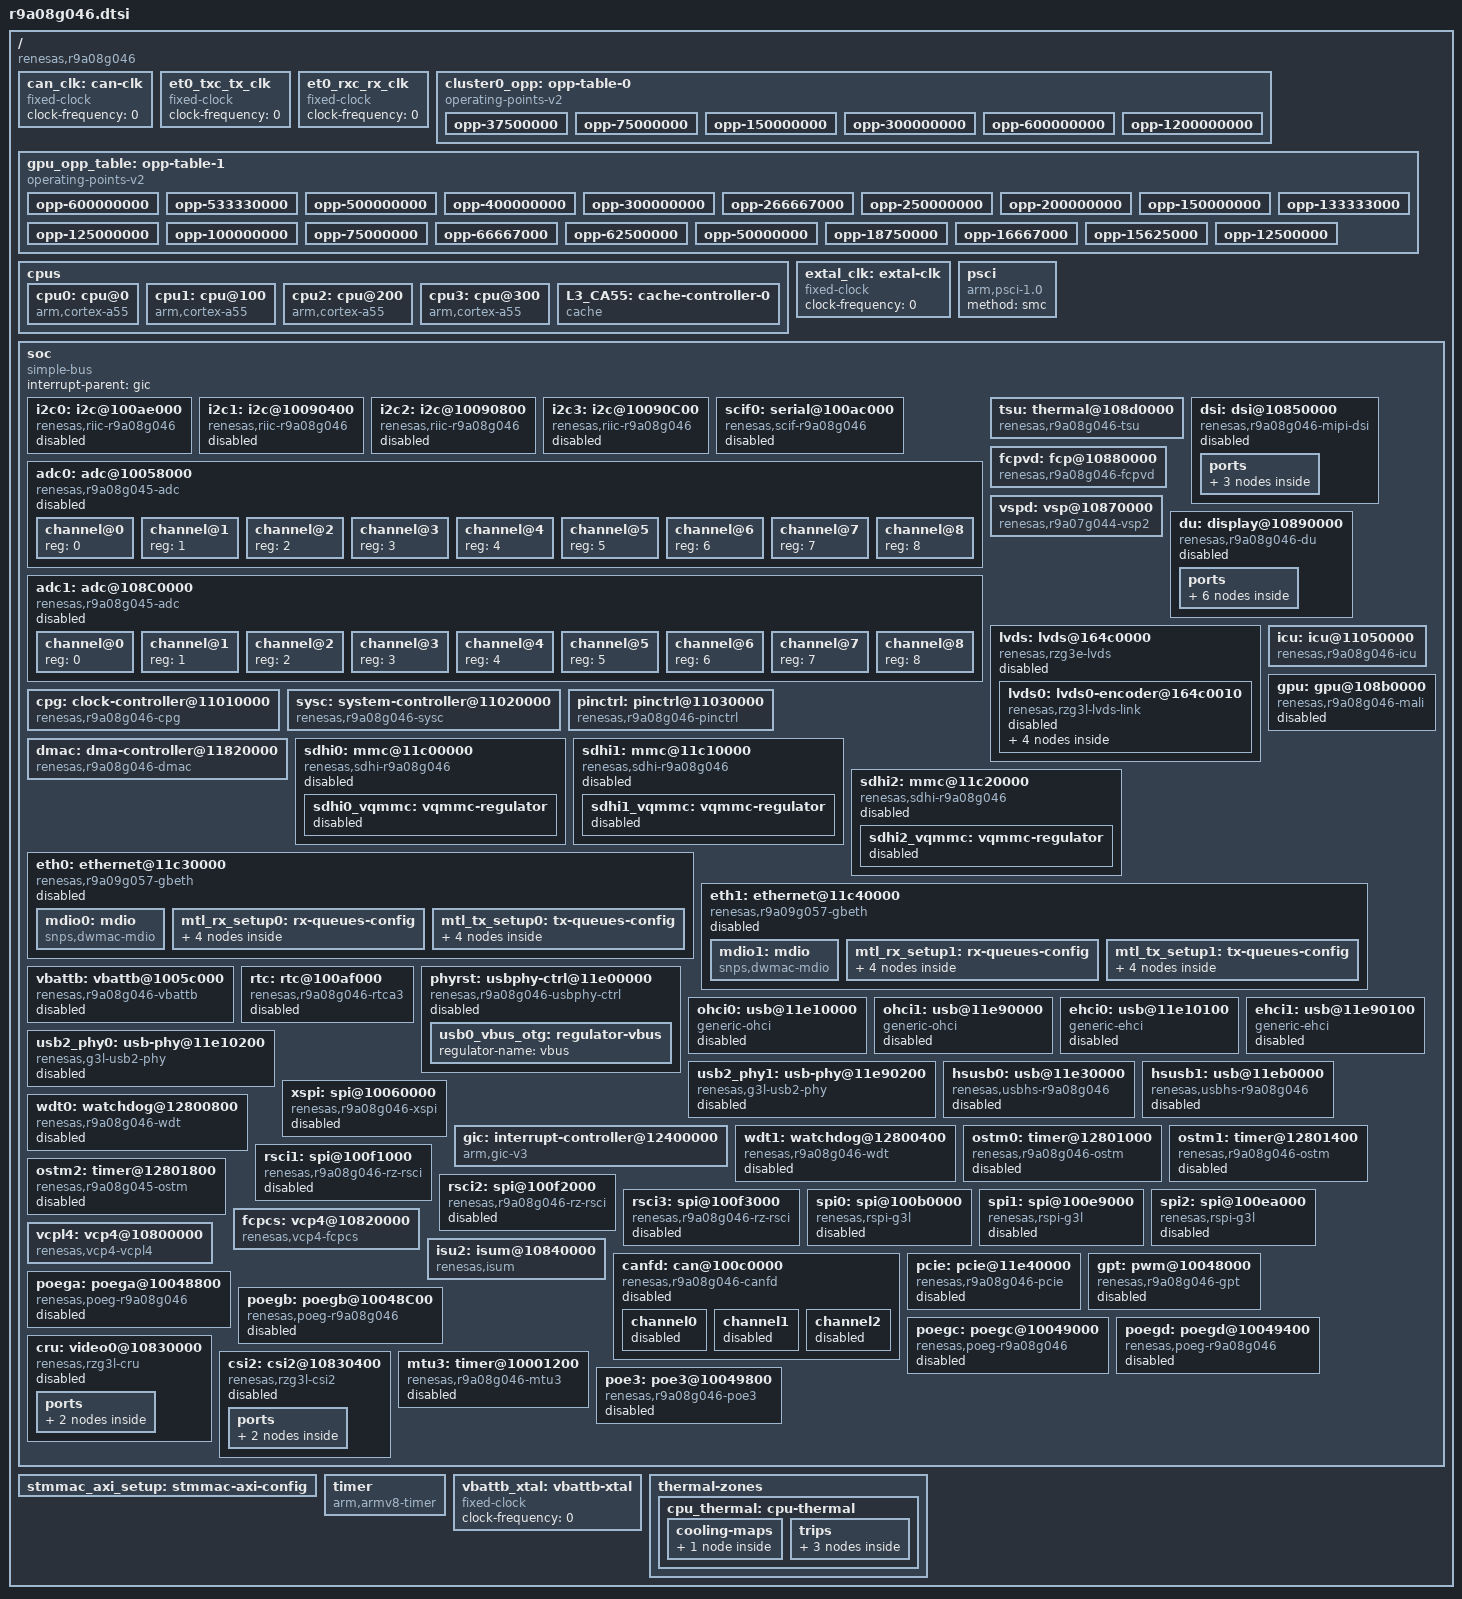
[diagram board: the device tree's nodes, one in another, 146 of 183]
// SPDX-License-Identifier: (GPL-2.0-only OR BSD-2-Clause)
/*
 * Device Tree Source for the RZ/G3L SoC
 *
 * Copyright (C) 2024 Renesas Electronics Corp.
 */

#include <dt-bindings/interrupt-controller/arm-gic.h>
#include <dt-bindings/clock/r9a08g046-cpg.h>
#include <dt-bindings/clock/renesas,r9a08g046-vbattb.h>

/ {
	compatible = "renesas,r9a08g046";
	#address-cells = <2>;
	#size-cells = <2>;

	/* External CAN clock - to be overridden by boards that provide it */
	can_clk: can-clk {
		compatible = "fixed-clock";
		#clock-cells = <0>;
		clock-frequency = <0>;
	};

	/* et0_txc_tx_clk clock input */
	et0_txc_tx_clk: et0_txc_tx_clk {
		compatible = "fixed-clock";
		#clock-cells = <0>;
		/* This value must be overridden by the board */
		clock-frequency = <0>;
	};

	/* et0_rxc_rx_clk clock input */
	et0_rxc_rx_clk: et0_rxc_rx_clk {
		compatible = "fixed-clock";
		#clock-cells = <0>;
		/* This value must be overridden by the board */
		clock-frequency = <0>;
	};

	cluster0_opp: opp-table-0 {
		compatible = "operating-points-v2";

		opp-37500000 {
			opp-hz = /bits/ 64 <37500000>;
			opp-microvolt = <1000000>;
			clock-latency-ns = <300000>;
		};
		opp-75000000 {
			opp-hz = /bits/ 64 <75000000>;
			opp-microvolt = <1000000>;
			clock-latency-ns = <300000>;
		};
		opp-150000000 {
			opp-hz = /bits/ 64 <150000000>;
			opp-microvolt = <1000000>;
			clock-latency-ns = <300000>;
		};
		opp-300000000 {
			opp-hz = /bits/ 64 <300000000>;
			opp-microvolt = <1000000>;
			clock-latency-ns = <300000>;
		};
		opp-600000000 {
			opp-hz = /bits/ 64 <600000000>;
			opp-microvolt = <1000000>;
			clock-latency-ns = <300000>;
		};
		opp-1200000000 {
			opp-hz = /bits/ 64 <1200000000>;
			opp-microvolt = <1000000>;
			clock-latency-ns = <300000>;
			opp-suspend;
		};
	};

	gpu_opp_table: opp-table-1 {
		compatible = "operating-points-v2";

		opp-600000000 {
		        opp-hz = /bits/ 64 <600000000>;
		        opp-microvolt = <1000000>;
		};

		opp-533330000 {
		        opp-hz = /bits/ 64 <533330000>;
		        opp-microvolt = <1000000>;
		};

		opp-500000000 {
		        opp-hz = /bits/ 64 <500000000>;
		        opp-microvolt = <1000000>;
		};

		opp-400000000 {
		        opp-hz = /bits/ 64 <400000000>;
		        opp-microvolt = <1000000>;
		};

		opp-300000000 {
		        opp-hz = /bits/ 64 <300000000>;
		        opp-microvolt = <1000000>;
		};

		opp-266667000 {
			opp-hz = /bits/ 64 <266667000>;
			opp-microvolt = <1000000>;
		};

		opp-250000000 {
			opp-hz = /bits/ 64 <250000000>;
			opp-microvolt = <1000000>;
		};

		opp-200000000 {
			opp-hz = /bits/ 64 <200000000>;
			opp-microvolt = <1000000>;
		};

		opp-150000000 {
			opp-hz = /bits/ 64 <150000000>;
			opp-microvolt = <1000000>;
		};

		opp-133333000 {
			opp-hz = /bits/ 64 <133333000>;
			opp-microvolt = <1000000>;
		};

		opp-125000000 {
			opp-hz = /bits/ 64 <125000000>;
			opp-microvolt = <1000000>;
		};

		opp-100000000 {
			opp-hz = /bits/ 64 <100000000>;
			opp-microvolt = <1000000>;
		};

		opp-75000000 {
			opp-hz = /bits/ 64 <75000000>;
			opp-microvolt = <1000000>;
		};

		opp-66667000 {
			opp-hz = /bits/ 64 <66667000>;
			opp-microvolt = <1000000>;
		};

		opp-62500000 {
			opp-hz = /bits/ 64 <62500000>;
			opp-microvolt = <1000000>;
		};

		opp-50000000 {
			opp-hz = /bits/ 64 <50000000>;
			opp-microvolt = <1000000>;
		};

		opp-18750000 {
			opp-hz = /bits/ 64 <18750000>;
			opp-microvolt = <1000000>;
		};

		opp-16667000 {
			opp-hz = /bits/ 64 <16667000>;
			opp-microvolt = <1000000>;
		};

		opp-15625000 {
			opp-hz = /bits/ 64 <15625000>;
			opp-microvolt = <1000000>;
		};

		opp-12500000 {
			opp-hz = /bits/ 64 <12500000>;
			opp-microvolt = <1000000>;
		};
	};

	cpus {
		#address-cells = <1>;
		#size-cells = <0>;

		cpu0: cpu@0 {
			compatible = "arm,cortex-a55";
			reg = <0>;
			device_type = "cpu";
			next-level-cache = <&L3_CA55>;
			enable-method = "psci";
			clocks = <&cpg CPG_CORE R9A08G046_CLK_IC0>;
			#cooling-cells = <2>;
			operating-points-v2 = <&cluster0_opp>;
		};

		cpu1: cpu@100 {
			compatible = "arm,cortex-a55";
			reg = <0x100>;
			device_type = "cpu";
			next-level-cache = <&L3_CA55>;
			enable-method = "psci";
			clocks = <&cpg CPG_CORE R9A08G046_CLK_IC1>;
			#cooling-cells = <2>;
			operating-points-v2 = <&cluster0_opp>;
		};

		cpu2: cpu@200 {
			compatible = "arm,cortex-a55";
			reg = <0x200>;
			device_type = "cpu";
			next-level-cache = <&L3_CA55>;
			enable-method = "psci";
			clocks = <&cpg CPG_CORE R9A08G046_CLK_IC2>;
			#cooling-cells = <2>;
			operating-points-v2 = <&cluster0_opp>;
		};

		cpu3: cpu@300 {
			compatible = "arm,cortex-a55";
			reg = <0x300>;
			device_type = "cpu";
			next-level-cache = <&L3_CA55>;
			enable-method = "psci";
			clocks = <&cpg CPG_CORE R9A08G046_CLK_IC3>;
			#cooling-cells = <2>;
			operating-points-v2 = <&cluster0_opp>;
		};

		L3_CA55: cache-controller-0 {
			compatible = "cache";
			cache-level = <3>;
			cache-unified;
			cache-size = <0x80000>;
		};
	};

	extal_clk: extal-clk {
		compatible = "fixed-clock";
		#clock-cells = <0>;
		/* This value must be overridden by the board. */
		clock-frequency = <0>;
	};

	psci {
		compatible = "arm,psci-1.0", "arm,psci-0.2";
		method = "smc";
	};

	soc: soc {
		compatible = "simple-bus";
		interrupt-parent = <&gic>;
		#address-cells = <2>;
		#size-cells = <2>;
		ranges;

		i2c0: i2c@100ae000 {
			#address-cells = <1>;
			#size-cells = <0>;
			compatible = "renesas,riic-r9a08g046";
			reg = <0 0x100AE000 0 0x400>;
			interrupts = <GIC_SPI 322 IRQ_TYPE_LEVEL_HIGH>,
				     <GIC_SPI 328 IRQ_TYPE_EDGE_RISING>,
				     <GIC_SPI 329 IRQ_TYPE_EDGE_RISING>,
				     <GIC_SPI 324 IRQ_TYPE_LEVEL_HIGH>,
				     <GIC_SPI 325 IRQ_TYPE_LEVEL_HIGH>,
				     <GIC_SPI 323 IRQ_TYPE_LEVEL_HIGH>,
				     <GIC_SPI 326 IRQ_TYPE_LEVEL_HIGH>,
				     <GIC_SPI 327 IRQ_TYPE_LEVEL_HIGH>;
			interrupt-names = "tei", "ri", "ti", "spi", "sti",
					  "naki", "ali", "tmoi";
			clocks = <&cpg CPG_MOD R9A08G046_I2C0_PCLK>;
			clock-frequency = <100000>;
			resets = <&cpg R9A08G046_I2C0_MRST>;
			power-domains = <&cpg>;
			status = "disabled";
		};

		i2c1: i2c@10090400 {
			#address-cells = <1>;
			#size-cells = <0>;
			compatible = "renesas,riic-r9a08g046";
			reg = <0 0x10090400 0 0x400>;
			interrupts = <GIC_SPI 330 IRQ_TYPE_LEVEL_HIGH>,
				     <GIC_SPI 336 IRQ_TYPE_EDGE_RISING>,
				     <GIC_SPI 337 IRQ_TYPE_EDGE_RISING>,
				     <GIC_SPI 332 IRQ_TYPE_LEVEL_HIGH>,
				     <GIC_SPI 333 IRQ_TYPE_LEVEL_HIGH>,
				     <GIC_SPI 331 IRQ_TYPE_LEVEL_HIGH>,
				     <GIC_SPI 334 IRQ_TYPE_LEVEL_HIGH>,
				     <GIC_SPI 335 IRQ_TYPE_LEVEL_HIGH>;
			interrupt-names = "tei", "ri", "ti", "spi", "sti",
					  "naki", "ali", "tmoi";
			clocks = <&cpg CPG_MOD R9A08G046_I2C1_PCLK>;
			clock-frequency = <100000>;
			resets = <&cpg R9A08G046_I2C1_MRST>;
			power-domains = <&cpg>;
			status = "disabled";
		};

		i2c2: i2c@10090800 {
			#address-cells = <1>;
			#size-cells = <0>;
			compatible = "renesas,riic-r9a08g046";
			reg = <0 0x10090800 0 0x400>;
			interrupts = <GIC_SPI 338 IRQ_TYPE_LEVEL_HIGH>,
				     <GIC_SPI 344 IRQ_TYPE_EDGE_RISING>,
				     <GIC_SPI 345 IRQ_TYPE_EDGE_RISING>,
				     <GIC_SPI 340 IRQ_TYPE_LEVEL_HIGH>,
				     <GIC_SPI 341 IRQ_TYPE_LEVEL_HIGH>,
				     <GIC_SPI 339 IRQ_TYPE_LEVEL_HIGH>,
				     <GIC_SPI 342 IRQ_TYPE_LEVEL_HIGH>,
				     <GIC_SPI 343 IRQ_TYPE_LEVEL_HIGH>;
			interrupt-names = "tei", "ri", "ti", "spi", "sti",
					  "naki", "ali", "tmoi";
			clocks = <&cpg CPG_MOD R9A08G046_I2C2_PCLK>;
			clock-frequency = <100000>;
			resets = <&cpg R9A08G046_I2C2_MRST>;
			power-domains = <&cpg>;
			status = "disabled";
		};

		i2c3: i2c@10090C00 {
			#address-cells = <1>;
			#size-cells = <0>;
			compatible = "renesas,riic-r9a08g046";
			reg = <0 0x10090C00 0 0x400>;
			interrupts = <GIC_SPI 346 IRQ_TYPE_LEVEL_HIGH>,
				     <GIC_SPI 352 IRQ_TYPE_EDGE_RISING>,
				     <GIC_SPI 353 IRQ_TYPE_EDGE_RISING>,
				     <GIC_SPI 348 IRQ_TYPE_LEVEL_HIGH>,
				     <GIC_SPI 349 IRQ_TYPE_LEVEL_HIGH>,
				     <GIC_SPI 347 IRQ_TYPE_LEVEL_HIGH>,
				     <GIC_SPI 350 IRQ_TYPE_LEVEL_HIGH>,
				     <GIC_SPI 351 IRQ_TYPE_LEVEL_HIGH>;
			interrupt-names = "tei", "ri", "ti", "spi", "sti",
					  "naki", "ali", "tmoi";
			clocks = <&cpg CPG_MOD R9A08G046_I2C3_PCLK>;
			clock-frequency = <100000>;
			resets = <&cpg R9A08G046_I2C3_MRST>;
			power-domains = <&cpg>;
			status = "disabled";
		};

		scif0: serial@100ac000 {
			compatible = "renesas,scif-r9a08g046", "renesas,scif-r9a07g044";
			reg = <0 0x100ac000 0 0x400>;
			interrupts = <GIC_SPI 386 IRQ_TYPE_LEVEL_HIGH>,
				     <GIC_SPI 388 IRQ_TYPE_LEVEL_HIGH>,
				     <GIC_SPI 389 IRQ_TYPE_LEVEL_HIGH>,
				     <GIC_SPI 387 IRQ_TYPE_LEVEL_HIGH>,
				     <GIC_SPI 390 IRQ_TYPE_LEVEL_HIGH>,
				     <GIC_SPI 390 IRQ_TYPE_LEVEL_HIGH>;
			interrupt-names = "eri", "rxi", "txi",
					  "bri", "dri", "tei";
			clocks = <&cpg CPG_MOD R9A08G046_SCIF0_CLK_PCK>;
			clock-names = "fck";
			power-domains = <&cpg>;
			resets = <&cpg R9A08G046_SCIF0_RST_SYSTEM_N>;
			status = "disabled";
		};

		adc0: adc@10058000 {
			compatible = "renesas,r9a08g045-adc";
			reg = <0 0x10058000 0 0x400>;
			interrupts = <GIC_SPI 377 IRQ_TYPE_EDGE_RISING>;
			clocks = <&cpg CPG_MOD R9A08G046_ADC0_ADCLK>,
				 <&cpg CPG_MOD R9A08G046_ADC0_PCLK>;
			clock-names = "adclk", "pclk";
			resets = <&cpg R9A08G046_ADC0_PRESETN>,
				 <&cpg R9A08G046_ADC0_ADRST_N>;
			reset-names = "presetn", "adrst-n";
			power-domains = <&cpg>;
			status = "disabled";

			#io-channel-cells = <1>;
			#address-cells = <1>;
			#size-cells = <0>;

			channel@0 {
				reg = <0>;
			};

			channel@1 {
				reg = <1>;
			};

			channel@2 {
				reg = <2>;
			};

			channel@3 {
				reg = <3>;
			};

			channel@4 {
				reg = <4>;
			};

			channel@5 {
				reg = <5>;
			};

			channel@6 {
				reg = <6>;
			};

			channel@7 {
				reg = <7>;
			};

			channel@8 {
				reg = <8>;
			};
		};

		adc1: adc@108C0000 {
			compatible = "renesas,r9a08g045-adc";
			reg = <0 0x108C0000 0 0x400>;
			interrupts = <GIC_SPI 378 IRQ_TYPE_EDGE_RISING>;
			clocks = <&cpg CPG_MOD R9A08G046_ADC1_ADCLK>,
				 <&cpg CPG_MOD R9A08G046_ADC1_PCLK>;
			clock-names = "adclk", "pclk";
			resets = <&cpg R9A08G046_ADC1_PRESETN>,
				 <&cpg R9A08G046_ADC1_ADRST_N>;
			reset-names = "presetn", "adrst-n";
			power-domains = <&cpg>;
			status = "disabled";

			#io-channel-cells = <1>;
			#address-cells = <1>;
			#size-cells = <0>;

			channel@0 {
				reg = <0>;
			};

			channel@1 {
				reg = <1>;
			};

			channel@2 {
				reg = <2>;
			};

			channel@3 {
				reg = <3>;
			};

			channel@4 {
				reg = <4>;
			};

			channel@5 {
				reg = <5>;
			};

			channel@6 {
				reg = <6>;
			};

			channel@7 {
				reg = <7>;
			};

			channel@8 {
				reg = <8>;
			};
		};

		tsu: thermal@108d0000 {
			compatible = "renesas,r9a08g046-tsu";
			reg = <0 0x108d0000 0 0x1000>;
			clocks = <&cpg CPG_MOD R9A08G046_TSU_PCLK>;
			resets = <&cpg R9A08G046_TSU_PRESETN>;
			power-domains = <&cpg>;
			#thermal-sensor-cells = <0>;
			io-channels = <&adc1 8>;
			io-channel-names = "tsu";
		};

		dsi: dsi@10850000 {
			compatible = "renesas,r9a08g046-mipi-dsi",
				     "renesas,rzg2l-mipi-dsi";
			reg = <0 0x10850000 0 0x20000>;
			interrupts = <GIC_SPI 170 IRQ_TYPE_LEVEL_HIGH>,
				     <GIC_SPI 171 IRQ_TYPE_LEVEL_HIGH>,
				     <GIC_SPI 172 IRQ_TYPE_LEVEL_HIGH>,
				     <GIC_SPI 173 IRQ_TYPE_LEVEL_HIGH>,
				     <GIC_SPI 174 IRQ_TYPE_LEVEL_HIGH>,
				     <GIC_SPI 175 IRQ_TYPE_LEVEL_HIGH>,
				     <GIC_SPI 176 IRQ_TYPE_LEVEL_HIGH>;
			interrupt-names = "seq0", "seq1", "vin1", "rcv",
					  "ferr", "ppi", "debug";
			clocks = <&cpg CPG_MOD R9A08G046_MIPI_DSI_SYSCLK>,
				 <&cpg CPG_MOD R9A08G046_MIPI_DSI_ACLK>,
				 <&cpg CPG_MOD R9A08G046_MIPI_DSI_PCLK>,
				 <&cpg CPG_MOD R9A08G046_MIPI_DSI_VCLK>,
				 <&cpg CPG_MOD R9A08G046_MIPI_DSI_LPCLK>;
			clock-names = "sysclk", "aclk", "pclk", "vclk", "lpclk";
			resets = <&cpg R9A08G046_MIPI_DSI_CMN_RSTB>,
				 <&cpg R9A08G046_MIPI_DSI_ARESET_N>,
				 <&cpg R9A08G046_MIPI_DSI_PRESET_N>;
			reset-names = "rst", "arst", "prst";
			power-domains = <&cpg>;
			status = "disabled";

			ports {
				#address-cells = <1>;
				#size-cells = <0>;

				port@0 {
					reg = <0>;
					dsi0_in: endpoint {
						remote-endpoint = <&du_out_dsi0>;
					};
				};

				port@1 {
					reg = <1>;
				};
			};
		};

		fcpvd: fcp@10880000 {
			compatible = "renesas,r9a08g046-fcpvd",
				     "renesas,fcpv";
			reg = <0 0x10880000 0 0x10000>;
			clocks = <&cpg CPG_MOD R9A08G046_LCDC_CLK_A>,
				 <&cpg CPG_MOD R9A08G046_LCDC_CLK_P>,
				 <&cpg CPG_MOD R9A08G046_LCDC_CLK_D>;
			clock-names = "aclk", "pclk", "vclk";
			resets = <&cpg R9A08G046_LCDC_RESET_N>;
			power-domains = <&cpg>;
		};

		vspd: vsp@10870000 {
			compatible = "renesas,r9a07g044-vsp2";
			reg = <0 0x10870000 0 0x10000>;
			interrupts = <GIC_SPI 177 IRQ_TYPE_LEVEL_HIGH>;
			clocks = <&cpg CPG_MOD R9A08G046_LCDC_CLK_A>,
				 <&cpg CPG_MOD R9A08G046_LCDC_CLK_P>,
				 <&cpg CPG_MOD R9A08G046_LCDC_CLK_D>;
			clock-names = "aclk", "pclk", "vclk";
			resets = <&cpg R9A08G046_LCDC_RESET_N>;
			power-domains = <&cpg>;
			renesas,fcp = <&fcpvd>;
		};

		du: display@10890000 {
			compatible = "renesas,r9a08g046-du";
			reg = <0 0x10890000 0 0x10000>;
			interrupts = <GIC_SPI 178 IRQ_TYPE_LEVEL_HIGH>;
			clocks = <&cpg CPG_MOD R9A08G046_LCDC_CLK_A>,
				 <&cpg CPG_MOD R9A08G046_LCDC_CLK_P>,
				 <&cpg CPG_MOD R9A08G046_LCDC_CLK_D>;
			clock-names = "aclk", "pclk", "vclk";
			power-domains = <&cpg>;
			resets = <&cpg R9A08G046_LCDC_RESET_N>,
				 <&cpg R9A08G046_LCDC_RESET_N>;
			renesas,vsps = <&vspd 0>;
			status = "disabled";

			ports {
				#address-cells = <1>;
				#size-cells = <0>;

				port@0 {
					reg = <0>;
					du_out_dsi0: endpoint {
						remote-endpoint = <&dsi0_in>;
					};
				};

				port@1 {
					reg = <1>;
					du_out_rgb: endpoint {
					};
				};

				port@2 {
					reg = <2>;
					du_out_lvds0: endpoint {
						remote-endpoint = <&lvds0_in>;
					};
				};
			};
		};


		lvds: lvds@164c0000 {
			compatible = "renesas,rzg3e-lvds";
			reg = <0x0 0x108a0000 0x0 0x10>;
			clocks = <&cpg CPG_MOD R9A08G046_MIPI_DSI_PCLK>;
			clock-names = "dsi_pclk";
			resets = <&cpg R9A08G046_LVDS_RESET_N>,
				 <&cpg R9A08G046_MIPI_DSI_PRESET_N>;
			power-domains = <&cpg>;
			status = "disabled";
			ranges;
			#address-cells = <2>;
			#size-cells = <2>;

			lvds0: lvds0-encoder@164c0010 {
				compatible = "renesas,rzg3l-lvds-link";
				reg = <0x0 0x108a0010 0x0 0x8>;
				clocks = <&cpg CPG_MOD R9A08G046_LVDS_PLLCLK>,
					 <&cpg CPG_MOD R9A08G046_LVDS_CLK_DOT0>;
				clock-names = "phyclk", "dotclk";
				power-domains = <&cpg>;
				renesas,id = <0>;
				status = "disabled";

				ports {
					#address-cells = <1>;
					#size-cells = <0>;

					port@0 {
						reg = <0>;
						lvds0_in: endpoint {
							remote-endpoint = <&du_out_lvds0>;
						};
					};

					port@1 {
						reg = <1>;
					};
				};
			};
		};

		cpg: clock-controller@11010000 {
			compatible = "renesas,r9a08g046-cpg";
			reg = <0 0x11010000 0 0x10000>;
			clocks = <&extal_clk>,
				 <&et0_txc_tx_clk>, <&et0_rxc_rx_clk>;
			clock-names = "extal",
				"et0_txc_tx_clk_in", "et0_rxc_rx_clk_in";
			#clock-cells = <2>;
			#reset-cells = <1>;
			#power-domain-cells = <0>;
		};

		sysc: system-controller@11020000 {
			compatible = "renesas,r9a08g046-sysc", "syscon";
			reg = <0 0x11020000 0 0x10000>;
			interrupts = <GIC_SPI 44 IRQ_TYPE_LEVEL_HIGH>,
				     <GIC_SPI 45 IRQ_TYPE_LEVEL_HIGH>,
				     <GIC_SPI 46 IRQ_TYPE_LEVEL_HIGH>,
				     <GIC_SPI 47 IRQ_TYPE_LEVEL_HIGH>;
			interrupt-names = "lpm_int", "ca55stbydone_int",
					  "cm33stbyr_int", "ca55_deny";
		};

		pinctrl: pinctrl@11030000 {
			compatible = "renesas,r9a08g046-pinctrl";
			syscon = <&sysc>;
			reg = <0 0x11030000 0 0x10000>;
			gpio-controller;
			#gpio-cells = <2>;
			interrupt-controller;
			#interrupt-cells = <2>;
			gpio-ranges = <&pinctrl 0 0 232>;
			interrupt-parent = <&icu>;
			clocks = <&cpg CPG_MOD R9A08G046_GPIO_HCLK>;
			power-domains = <&cpg>;
			resets = <&cpg R9A08G046_GPIO_RSTN>,
				 <&cpg R9A08G046_GPIO_PORT_RESETN>,
				 <&cpg R9A08G046_GPIO_SPARE_RESETN>;
		};

		icu: icu@11050000 {
			compatible = "renesas,r9a08g046-icu";
			#interrupt-cells = <2>;
			#address-cells = <0>;
			interrupt-controller;
			reg = <0 0x11050000 0 0x10000>;
			interrupts = <GIC_SPI 0 IRQ_TYPE_LEVEL_HIGH>,
				     <GIC_SPI 1 IRQ_TYPE_LEVEL_HIGH>,
				     <GIC_SPI 2 IRQ_TYPE_LEVEL_HIGH>,
				     <GIC_SPI 3 IRQ_TYPE_LEVEL_HIGH>,
				     <GIC_SPI 4 IRQ_TYPE_LEVEL_HIGH>,
				     <GIC_SPI 5 IRQ_TYPE_LEVEL_HIGH>,
				     <GIC_SPI 6 IRQ_TYPE_LEVEL_HIGH>,
				     <GIC_SPI 7 IRQ_TYPE_LEVEL_HIGH>,
				     <GIC_SPI 8 IRQ_TYPE_LEVEL_HIGH>,
				     <GIC_SPI 529 IRQ_TYPE_LEVEL_HIGH>,
				     <GIC_SPI 530 IRQ_TYPE_LEVEL_HIGH>,
				     <GIC_SPI 531 IRQ_TYPE_LEVEL_HIGH>,
				     <GIC_SPI 532 IRQ_TYPE_LEVEL_HIGH>,
				     <GIC_SPI 533 IRQ_TYPE_LEVEL_HIGH>,
				     <GIC_SPI 534 IRQ_TYPE_LEVEL_HIGH>,
				     <GIC_SPI 535 IRQ_TYPE_LEVEL_HIGH>,
				     <GIC_SPI 536 IRQ_TYPE_LEVEL_HIGH>,
				     <GIC_SPI 505 IRQ_TYPE_LEVEL_HIGH>,
				     <GIC_SPI 506 IRQ_TYPE_LEVEL_HIGH>,
				     <GIC_SPI 507 IRQ_TYPE_LEVEL_HIGH>,
				     <GIC_SPI 508 IRQ_TYPE_LEVEL_HIGH>,
				     <GIC_SPI 509 IRQ_TYPE_LEVEL_HIGH>,
				     <GIC_SPI 510 IRQ_TYPE_LEVEL_HIGH>,
				     <GIC_SPI 511 IRQ_TYPE_LEVEL_HIGH>,
				     <GIC_SPI 512 IRQ_TYPE_LEVEL_HIGH>,
				     <GIC_SPI 513 IRQ_TYPE_LEVEL_HIGH>,
				     <GIC_SPI 514 IRQ_TYPE_LEVEL_HIGH>,
				     <GIC_SPI 515 IRQ_TYPE_LEVEL_HIGH>,
				     <GIC_SPI 516 IRQ_TYPE_LEVEL_HIGH>,
				     <GIC_SPI 517 IRQ_TYPE_LEVEL_HIGH>,
				     <GIC_SPI 518 IRQ_TYPE_LEVEL_HIGH>,
				     <GIC_SPI 519 IRQ_TYPE_LEVEL_HIGH>,
				     <GIC_SPI 520 IRQ_TYPE_LEVEL_HIGH>,
				     <GIC_SPI 521 IRQ_TYPE_LEVEL_HIGH>,
				     <GIC_SPI 522 IRQ_TYPE_LEVEL_HIGH>,
				     <GIC_SPI 523 IRQ_TYPE_LEVEL_HIGH>,
				     <GIC_SPI 524 IRQ_TYPE_LEVEL_HIGH>,
				     <GIC_SPI 525 IRQ_TYPE_LEVEL_HIGH>,
				     <GIC_SPI 526 IRQ_TYPE_LEVEL_HIGH>,
				     <GIC_SPI 527 IRQ_TYPE_LEVEL_HIGH>,
				     <GIC_SPI 528 IRQ_TYPE_LEVEL_HIGH>,
				     <GIC_SPI 529 IRQ_TYPE_LEVEL_HIGH>,
				     <GIC_SPI 530 IRQ_TYPE_LEVEL_HIGH>,
				     <GIC_SPI 531 IRQ_TYPE_LEVEL_HIGH>,
				     <GIC_SPI 532 IRQ_TYPE_LEVEL_HIGH>,
				     <GIC_SPI 533 IRQ_TYPE_LEVEL_HIGH>,
				     <GIC_SPI 534 IRQ_TYPE_LEVEL_HIGH>,
				     <GIC_SPI 535 IRQ_TYPE_LEVEL_HIGH>,
				     <GIC_SPI 536 IRQ_TYPE_LEVEL_HIGH>,
				     <GIC_SPI 33 IRQ_TYPE_LEVEL_HIGH>,
				     <GIC_SPI 35 IRQ_TYPE_LEVEL_HIGH>,
				     <GIC_SPI 36 IRQ_TYPE_LEVEL_HIGH>,
				     <GIC_SPI 37 IRQ_TYPE_LEVEL_HIGH>;
			interrupt-names = "nmi",
					  "irq0", "irq1", "irq2", "irq3",
					  "irq4", "irq5", "irq6", "irq7",
					  "irq8", "irq9", "irq10", "irq11",
					  "irq12", "irq13", "irq14", "irq15",
					  "tint0", "tint1", "tint2", "tint3",
					  "tint4", "tint5", "tint6", "tint7",
					  "tint8", "tint9", "tint10", "tint11",
					  "tint12", "tint13", "tint14", "tint15",
					  "tint16", "tint17", "tint18", "tint19",
					  "tint20", "tint21", "tint22", "tint23",
					  "tint24", "tint25", "tint26", "tint27",
					  "tint28", "tint29", "tint30", "tint31",
					  "bus-err", "ec7tie1-0", "ec7tie2-0",
					  "ec7tiovf-0";
			clocks = <&cpg CPG_MOD R9A08G046_IA55_CLK>,
				 <&cpg CPG_MOD R9A08G046_IA55_PCLK>;
			clock-names = "clk", "pclk";
			power-domains = <&cpg>;
			resets = <&cpg R9A08G046_IA55_RESETN>;
		};

		dmac: dma-controller@11820000 {
			compatible = "renesas,r9a08g046-dmac",
				     "renesas,rz-dmac";
			reg = <0 0x11820000 0 0x10000>,
			      <0 0x11830000 0 0x10000>;
			interrupts = <GIC_SPI 153 IRQ_TYPE_EDGE_RISING>,
				     <GIC_SPI 154 IRQ_TYPE_EDGE_RISING>,
				     <GIC_SPI 155 IRQ_TYPE_EDGE_RISING>,
				     <GIC_SPI 156 IRQ_TYPE_EDGE_RISING>,
				     <GIC_SPI 157 IRQ_TYPE_EDGE_RISING>,
				     <GIC_SPI 158 IRQ_TYPE_EDGE_RISING>,
				     <GIC_SPI 159 IRQ_TYPE_EDGE_RISING>,
				     <GIC_SPI 160 IRQ_TYPE_EDGE_RISING>,
				     <GIC_SPI 161 IRQ_TYPE_EDGE_RISING>,
				     <GIC_SPI 162 IRQ_TYPE_EDGE_RISING>,
				     <GIC_SPI 163 IRQ_TYPE_EDGE_RISING>,
				     <GIC_SPI 164 IRQ_TYPE_EDGE_RISING>,
				     <GIC_SPI 165 IRQ_TYPE_EDGE_RISING>,
				     <GIC_SPI 166 IRQ_TYPE_EDGE_RISING>,
				     <GIC_SPI 167 IRQ_TYPE_EDGE_RISING>,
				     <GIC_SPI 168 IRQ_TYPE_EDGE_RISING>,
				     <GIC_SPI 169 IRQ_TYPE_EDGE_RISING>;
			interrupt-names = "error",
					  "ch0", "ch1", "ch2", "ch3",
					  "ch4", "ch5", "ch6", "ch7",
					  "ch8", "ch9", "ch10", "ch11",
					  "ch12", "ch13", "ch14", "ch15";
			clocks = <&cpg CPG_MOD R9A08G046_DMAC_ACLK>,
				 <&cpg CPG_MOD R9A08G046_DMAC_PCLK>;
			clock-names = "main", "register";
			power-domains = <&cpg>;
			resets = <&cpg R9A08G046_DMAC_ARESETN>,
				 <&cpg R9A08G046_DMAC_RST_ASYNC>;
			reset-names = "arst", "rst_async";
			#dma-cells = <1>;
			dma-channels = <16>;
		};

		sdhi0: mmc@11c00000  {
			compatible = "renesas,sdhi-r9a08g046", "renesas,rzg2l-sdhi";
			reg = <0x0 0x11c00000 0 0x10000>;
			interrupts = <GIC_SPI 130 IRQ_TYPE_LEVEL_HIGH>,
				     <GIC_SPI 131 IRQ_TYPE_LEVEL_HIGH>;
			clocks = <&cpg CPG_MOD R9A08G046_SDHI0_IMCLK>,
				 <&cpg CPG_MOD R9A08G046_SDHI0_CLK_HS>,
				 <&cpg CPG_MOD R9A08G046_SDHI0_IMCLK2>,
				 <&cpg CPG_MOD R9A08G046_SDHI0_IACLKS>,
				 <&cpg CPG_MOD R9A08G046_SDHI0_IACLKM>;
			clock-names = "core", "clkh", "cd", "aclk", "aclkm";
			resets = <&cpg R9A08G046_SDHI0_IXRST>,
				 <&cpg R9A08G046_SDHI0_IXRSTAXIM>,
				 <&cpg R9A08G046_SDHI0_IXRSTAXIS>;
			reset-names = "rst", "axim", "axis";
			power-domains = <&cpg>;
			status = "disabled";

			sdhi0_vqmmc: vqmmc-regulator {
				regulator-name = "SDHI0-VQMMC";
				regulator-min-microvolt = <1800000>;
				regulator-max-microvolt = <3300000>;
				status = "disabled";
			};
		};

		sdhi1: mmc@11c10000  {
			compatible = "renesas,sdhi-r9a08g046", "renesas,rzg2l-sdhi";
			reg = <0x0 0x11c10000 0 0x10000>;
			interrupts = <GIC_SPI 132 IRQ_TYPE_LEVEL_HIGH>,
				     <GIC_SPI 133 IRQ_TYPE_LEVEL_HIGH>;
			clocks = <&cpg CPG_MOD R9A08G046_SDHI1_IMCLK>,
				 <&cpg CPG_MOD R9A08G046_SDHI1_CLK_HS>,
				 <&cpg CPG_MOD R9A08G046_SDHI1_IMCLK2>,
				 <&cpg CPG_MOD R9A08G046_SDHI1_IACLKS>,
				 <&cpg CPG_MOD R9A08G046_SDHI1_IACLKM>;
			clock-names = "core", "clkh", "cd", "aclk", "iclkm";
			resets = <&cpg R9A08G046_SDHI1_IXRST>,
				 <&cpg R9A08G046_SDHI1_IXRSTAXIM>,
				 <&cpg R9A08G046_SDHI1_IXRSTAXIS>;
			reset-names = "rst", "axim", "axis";
			power-domains = <&cpg>;
			status = "disabled";

			sdhi1_vqmmc: vqmmc-regulator {
				regulator-name = "SDHI1-VQMMC";
				regulator-min-microvolt = <1800000>;
				regulator-max-microvolt = <3300000>;
				status = "disabled";
			};
		};

		sdhi2: mmc@11c20000  {
			compatible = "renesas,sdhi-r9a08g046", "renesas,rzg2l-sdhi";
			reg = <0x0 0x11c20000 0 0x10000>;
			interrupts = <GIC_SPI 134 IRQ_TYPE_LEVEL_HIGH>,
				     <GIC_SPI 135 IRQ_TYPE_LEVEL_HIGH>;
			clocks = <&cpg CPG_MOD R9A08G046_SDHI2_IMCLK>,
				 <&cpg CPG_MOD R9A08G046_SDHI2_CLK_HS>,
				 <&cpg CPG_MOD R9A08G046_SDHI2_IMCLK2>,
				 <&cpg CPG_MOD R9A08G046_SDHI2_IACLKS>,
				 <&cpg CPG_MOD R9A08G046_SDHI2_IACLKM>;
			clock-names = "core", "clkh", "cd", "aclk", "iclkm";
			resets = <&cpg R9A08G046_SDHI2_IXRST>,
				 <&cpg R9A08G046_SDHI2_IXRSTAXIM>,
				 <&cpg R9A08G046_SDHI2_IXRSTAXIS>;
			reset-names = "rst", "axim", "axis";
			power-domains = <&cpg>;
			status = "disabled";

			sdhi2_vqmmc: vqmmc-regulator {
				regulator-name = "SDHI2-VQMMC";
				regulator-min-microvolt = <1800000>;
				regulator-max-microvolt = <3300000>;
				status = "disabled";
			};
		};

		gpu: gpu@108b0000 {
			compatible = "renesas,r9a08g046-mali",
				     "arm,mali-bifrost";
			reg = <0x0 0x108b0000 0x0 0x10000>;
			interrupts = <GIC_SPI 179 IRQ_TYPE_LEVEL_HIGH>,
				     <GIC_SPI 180 IRQ_TYPE_LEVEL_HIGH>,
				     <GIC_SPI 181 IRQ_TYPE_LEVEL_HIGH>,
				     <GIC_SPI 182 IRQ_TYPE_LEVEL_HIGH>;
			interrupt-names = "gpu", "job", "mmu", "event";
			clocks = <&cpg CPG_MOD R9A08G046_GE3D_CLK>,
				 <&cpg CPG_MOD R9A08G046_GE3D_AXI_CLK>,
				 <&cpg CPG_MOD R9A08G046_GE3D_ACE_CLK>;
			clock-names = "gpu", "bus", "bus_ace";
			power-domains = <&cpg>;
			resets = <&cpg R9A08G046_GE3D_RESETN>,
				 <&cpg R9A08G046_GE3D_AXI_RESETN>,
				 <&cpg R9A08G046_GE3D_ACE_RESETN>;
			reset-names = "rst", "axi_rst", "ace_rst";
			operating-points-v2 = <&gpu_opp_table>;
			status = "disabled";
		};

		eth0: ethernet@11c30000 {
			compatible = "renesas,r9a09g057-gbeth", "renesas,rzv2h-gbeth",
				     "snps,dwmac-5.20";
			reg = <0 0x11c30000 0 0x10000>;
			interrupts = <GIC_SPI 78 IRQ_TYPE_LEVEL_HIGH>,
				     <GIC_SPI 80 IRQ_TYPE_LEVEL_HIGH>,
				     <GIC_SPI 79 IRQ_TYPE_LEVEL_HIGH>,
				     <GIC_SPI 85 IRQ_TYPE_LEVEL_HIGH>,
				     <GIC_SPI 86 IRQ_TYPE_LEVEL_HIGH>,
				     <GIC_SPI 87 IRQ_TYPE_LEVEL_HIGH>,
				     <GIC_SPI 88 IRQ_TYPE_LEVEL_HIGH>,
				     <GIC_SPI 81 IRQ_TYPE_LEVEL_HIGH>,
				     <GIC_SPI 82 IRQ_TYPE_LEVEL_HIGH>,
				     <GIC_SPI 83 IRQ_TYPE_LEVEL_HIGH>,
				     <GIC_SPI 84 IRQ_TYPE_LEVEL_HIGH>;
			interrupt-names = "macirq", "eth_wake_irq", "eth_lpi",
					  "rx-queue-0", "rx-queue-1", "rx-queue-2",
					  "rx-queue-3", "tx-queue-0", "tx-queue-1",
					  "tx-queue-2", "tx-queue-3";
			clocks =  <&cpg CPG_MOD R9A08G046_ETH0_CLK_AXI>,
				  <&cpg CPG_MOD R9A08G046_ETH0_CLK_CHI>,
				  <&cpg CPG_MOD R9A08G046_ETH0_CLK_PTP_REF_I>,
				  <&cpg CPG_MOD R9A08G046_ETH0_CLK_TX_I>,
				  <&cpg CPG_MOD R9A08G046_ETH0_CLK_RX_I>,
				  <&cpg CPG_MOD R9A08G046_ETH0_CLK_TX_180_I>,
				  <&cpg CPG_MOD R9A08G046_ETH0_CLK_RX_180_I>;
			clock-names = "stmmaceth", "pclk", "ptp_ref",
				      "tx", "rx", "tx-180", "rx-180";
			resets = <&cpg R9A08G046_ETH0_ARESET_N>;
			power-domains = <&cpg>;
			snps,multicast-filter-bins = <256>;
			snps,perfect-filter-entries = <128>;
			rx-fifo-depth = <8192>;
			tx-fifo-depth = <8192>;
			snps,fixed-burst;
			snps,no-pbl-x8;
			snps,force_thresh_dma_mode;
			snps,en-tx-lpi-clockgating;
			snps,axi-config = <&stmmac_axi_setup>;
			snps,mtl-rx-config = <&mtl_rx_setup0>;
			snps,mtl-tx-config = <&mtl_tx_setup0>;
			snps,txpbl = <32>;
			snps,rxpbl = <32>;
			status = "disabled";

			mdio0: mdio {
				compatible = "snps,dwmac-mdio";
				#address-cells = <1>;
				#size-cells = <0>;
			};

			mtl_rx_setup0: rx-queues-config {
				snps,rx-queues-to-use = <4>;
				snps,rx-sched-sp;

				queue0 {
					snps,dcb-algorithm;
					snps,priority = <0x1>;
					snps,map-to-dma-channel = <0>;
				};

				queue1 {
					snps,dcb-algorithm;
					snps,priority = <0x2>;
					snps,map-to-dma-channel = <1>;
				};

				queue2 {
					snps,dcb-algorithm;
					snps,priority = <0x4>;
					snps,map-to-dma-channel = <2>;
				};

				queue3 {
					snps,dcb-algorithm;
					snps,priority = <0x8>;
					snps,map-to-dma-channel = <3>;
				};
			};

			mtl_tx_setup0: tx-queues-config {
				snps,tx-queues-to-use = <4>;
				snps,tx-sched-wrr;

				queue0 {
					snps,weight = <0x10>;
					snps,dcb-algorithm;
					snps,priority = <0x1>;
				};

				queue1 {
					snps,weight = <0x12>;
					snps,dcb-algorithm;
					snps,priority = <0x2>;
				};

				queue2 {
					snps,weight = <0x14>;
					snps,dcb-algorithm;
					snps,priority = <0x4>;
				};

				queue3 {
					snps,weight = <0x18>;
					snps,dcb-algorithm;
					snps,priority = <0x8>;
				};
			};
		};

		eth1: ethernet@11c40000 {
			compatible = "renesas,r9a09g057-gbeth", "renesas,rzv2h-gbeth",
				     "snps,dwmac-5.20";
			reg = <0 0x11c40000 0 0x10000>;
			interrupts = <GIC_SPI 93 IRQ_TYPE_LEVEL_HIGH>,
				     <GIC_SPI 95 IRQ_TYPE_LEVEL_HIGH>,
				     <GIC_SPI 94 IRQ_TYPE_LEVEL_HIGH>,
				     <GIC_SPI 100 IRQ_TYPE_LEVEL_HIGH>,
				     <GIC_SPI 101 IRQ_TYPE_LEVEL_HIGH>,
				     <GIC_SPI 102 IRQ_TYPE_LEVEL_HIGH>,
				     <GIC_SPI 103 IRQ_TYPE_LEVEL_HIGH>,
				     <GIC_SPI 96 IRQ_TYPE_LEVEL_HIGH>,
				     <GIC_SPI 97 IRQ_TYPE_LEVEL_HIGH>,
				     <GIC_SPI 98 IRQ_TYPE_LEVEL_HIGH>,
				     <GIC_SPI 99 IRQ_TYPE_LEVEL_HIGH>;
			interrupt-names = "macirq", "eth_wake_irq", "eth_lpi",
					  "rx-queue-0", "rx-queue-1", "rx-queue-2",
					  "rx-queue-3", "tx-queue-0", "tx-queue-1",
					  "tx-queue-2", "tx-queue-3";
			clocks =  <&cpg CPG_MOD R9A08G046_ETH1_CLK_AXI>,
				  <&cpg CPG_MOD R9A08G046_ETH1_CLK_CHI>,
				  <&cpg CPG_MOD R9A08G046_ETH1_CLK_PTP_REF_I>,
				  <&cpg CPG_MOD R9A08G046_ETH1_CLK_TX_I>,
				  <&cpg CPG_MOD R9A08G046_ETH1_CLK_RX_I>,
				  <&cpg CPG_MOD R9A08G046_ETH1_CLK_TX_180_I>,
				  <&cpg CPG_MOD R9A08G046_ETH1_CLK_RX_180_I>;
			clock-names = "stmmaceth", "pclk", "ptp_ref",
				      "tx", "rx", "tx-180", "rx-180";
			resets = <&cpg R9A08G046_ETH1_ARESET_N>;
			power-domains = <&cpg>;
			snps,multicast-filter-bins = <256>;
			snps,perfect-filter-entries = <128>;
			rx-fifo-depth = <8192>;
			tx-fifo-depth = <8192>;
			snps,fixed-burst;
			snps,no-pbl-x8;
			snps,force_thresh_dma_mode;
			snps,en-tx-lpi-clockgating;
			snps,axi-config = <&stmmac_axi_setup>;
			snps,mtl-rx-config = <&mtl_rx_setup1>;
			snps,mtl-tx-config = <&mtl_tx_setup1>;
			snps,txpbl = <32>;
			snps,rxpbl = <32>;
			status = "disabled";

			mdio1: mdio {
				compatible = "snps,dwmac-mdio";
				#address-cells = <1>;
				#size-cells = <0>;
			};

			mtl_rx_setup1: rx-queues-config {
				snps,rx-queues-to-use = <4>;
				snps,rx-sched-sp;

				queue0 {
					snps,dcb-algorithm;
					snps,priority = <0x1>;
					snps,map-to-dma-channel = <0>;
				};

				queue1 {
					snps,dcb-algorithm;
					snps,priority = <0x2>;
					snps,map-to-dma-channel = <1>;
				};

				queue2 {
					snps,dcb-algorithm;
					snps,priority = <0x4>;
					snps,map-to-dma-channel = <2>;
				};

				queue3 {
					snps,dcb-algorithm;
					snps,priority = <0x8>;
					snps,map-to-dma-channel = <3>;
				};
			};

			mtl_tx_setup1: tx-queues-config {
				snps,tx-queues-to-use = <4>;
				snps,tx-sched-wrr;

				queue0 {
					snps,weight = <0x10>;
					snps,dcb-algorithm;
					snps,priority = <0x1>;
				};

				queue1 {
					snps,weight = <0x12>;
					snps,dcb-algorithm;
					snps,priority = <0x2>;
				};

				queue2 {
					snps,weight = <0x14>;
					snps,dcb-algorithm;
					snps,priority = <0x4>;
				};

				queue3 {
					snps,weight = <0x18>;
					snps,dcb-algorithm;
					snps,priority = <0x8>;
				};
			};
		};

		vbattb: vbattb@1005c000 {
			compatible = "renesas,r9a08g046-vbattb";
			reg = <0 0x1005c000 0 0x1000>;
			interrupts = <GIC_SPI 48 IRQ_TYPE_LEVEL_HIGH>;
			clocks = <&cpg CPG_MOD R9A08G046_VBAT_BCLK>, <&vbattb_xtal>;
			clock-names = "bclk", "rtx";
			#clock-cells = <1>;
			power-domains = <&cpg>;
			resets = <&cpg R9A08G046_VBAT_BRESETN>;
			status = "disabled";
		};

		rtc: rtc@100af000 {
			compatible = "renesas,r9a08g046-rtca3", "renesas,rz-rtca3";
			reg = <0 0x100af000 0 0x400>;
			interrupts = <GIC_SPI 381 IRQ_TYPE_LEVEL_HIGH>,
				     <GIC_SPI 382 IRQ_TYPE_LEVEL_HIGH>,
				     <GIC_SPI 383 IRQ_TYPE_LEVEL_HIGH>;
			interrupt-names = "alarm", "carry", "period";
			clocks = <&cpg CPG_MOD R9A08G046_VBAT_BCLK>, <&vbattb VBATTB_VBATTCLK>;
			clock-names = "bus", "counter";
			power-domains = <&cpg>;
			resets = <&cpg R9A08G046_VBAT_BRESETN>;
			status = "disabled";
		};

		phyrst: usbphy-ctrl@11e00000 {
			compatible = "renesas,r9a08g046-usbphy-ctrl";
			reg = <0 0x11e00000 0 0x10000>;
			clocks = <&cpg CPG_MOD R9A08G046_USB_PCLK>;
			resets = <&cpg R9A08G046_USB_PRESETN>;
			power-domains = <&cpg>;
			#reset-cells = <1>;
			renesas,sysc-pwrrdy = <&sysc 0xd70 0x1>;
			status = "disabled";

			usb0_vbus_otg: regulator-vbus {
				regulator-name = "vbus";
			};
		};

		ohci0: usb@11e10000 {
			compatible = "generic-ohci";
			reg = <0 0x11e10000 0 0x100>;
			interrupts = <GIC_SPI 113 IRQ_TYPE_LEVEL_HIGH>;
			clocks = <&cpg CPG_MOD R9A08G046_USB_PCLK>,
				 <&cpg CPG_MOD R9A08G046_USB_U2H0_HCLK>;
			resets = <&phyrst 0>,
				 <&cpg R9A08G046_USB_U2H0_HRESETN>;
			phys = <&usb2_phy0 1>;
			phy-names = "usb";
			power-domains = <&cpg>;
			status = "disabled";
		};

		ohci1: usb@11e90000 {
			compatible = "generic-ohci";
			reg = <0 0x11e90000 0 0x100>;
			interrupts = <GIC_SPI 118 IRQ_TYPE_LEVEL_HIGH>;
			clocks = <&cpg CPG_MOD R9A08G046_USB_PCLK>,
				 <&cpg CPG_MOD R9A08G046_USB_U2H1_HCLK>;
			resets = <&phyrst 1>,
				 <&cpg R9A08G046_USB_U2H1_HRESETN>;
			phys = <&usb2_phy1 1>;
			phy-names = "usb";
			power-domains = <&cpg>;
			status = "disabled";
		};

		ehci0: usb@11e10100 {
			compatible = "generic-ehci";
			reg = <0 0x11e10100 0 0x100>;
			interrupts = <GIC_SPI 114 IRQ_TYPE_LEVEL_HIGH>;
			clocks = <&cpg CPG_MOD R9A08G046_USB_PCLK>,
				 <&cpg CPG_MOD R9A08G046_USB_U2H0_HCLK>;
			resets = <&phyrst 0>,
				 <&cpg R9A08G046_USB_U2H0_HRESETN>;
			phys = <&usb2_phy0 2>;
			phy-names = "usb";
			companion = <&ohci0>;
			power-domains = <&cpg>;
			status = "disabled";
		};

		ehci1: usb@11e90100 {
			compatible = "generic-ehci";
			reg = <0 0x11e90100 0 0x100>;
			interrupts = <GIC_SPI 119 IRQ_TYPE_LEVEL_HIGH>;
			clocks = <&cpg CPG_MOD R9A08G046_USB_PCLK>,
				 <&cpg CPG_MOD R9A08G046_USB_U2H1_HCLK>;
			resets = <&phyrst 1>,
				 <&cpg R9A08G046_USB_U2H1_HRESETN>;
			phys = <&usb2_phy1 2>;
			phy-names = "usb";
			companion = <&ohci1>;
			power-domains = <&cpg>;
			status = "disabled";
		};

		usb2_phy0: usb-phy@11e10200 {
			compatible = "renesas,g3l-usb2-phy";
			reg = <0 0x11e10200 0 0x700>;
			interrupts = <GIC_SPI 116 IRQ_TYPE_LEVEL_HIGH>;
			clocks = <&cpg CPG_MOD R9A08G046_USB_PCLK>,
				 <&cpg CPG_MOD R9A08G046_USB_U2H0_HCLK>;
			resets = <&phyrst 0>,
				 <&cpg R9A08G046_USB_U2H0_HRESETN>;
			#phy-cells = <1>;
			power-domains = <&cpg>;
			status = "disabled";
		};

		usb2_phy1: usb-phy@11e90200 {
			compatible = "renesas,g3l-usb2-phy";
			reg = <0 0x11e90200 0 0x700>;
			interrupts = <GIC_SPI 121 IRQ_TYPE_LEVEL_HIGH>;
			clocks = <&cpg CPG_MOD R9A08G046_USB_PCLK>,
				 <&cpg CPG_MOD R9A08G046_USB_U2H1_HCLK>;
			resets = <&phyrst 1>,
				 <&cpg R9A08G046_USB_U2H1_HRESETN>;
			#phy-cells = <1>;
			power-domains = <&cpg>;
			status = "disabled";
		};

		hsusb0: usb@11e30000 {
			compatible = "renesas,usbhs-r9a08g046",
				     "renesas,rzg2l-usbhs";
			reg = <0 0x11e30000 0 0x10000>;
			interrupts = <GIC_SPI 123 IRQ_TYPE_EDGE_RISING>,
				     <GIC_SPI 124 IRQ_TYPE_LEVEL_HIGH>,
				     <GIC_SPI 125 IRQ_TYPE_LEVEL_HIGH>,
				     <GIC_SPI 122 IRQ_TYPE_LEVEL_HIGH>;
			clocks = <&cpg CPG_MOD R9A08G046_USB_PCLK>,
				 <&cpg CPG_MOD R9A08G046_USB_U2P0_EXR_CPUCLK>;
			resets = <&phyrst 0>,
				 <&cpg R9A08G046_USB_U2P0_EXL_SYSRST>;
			renesas,buswait = <7>;
			phys = <&usb2_phy0 3>;
			phy-names = "usb";
			power-domains = <&cpg>;
			status = "disabled";
		};

		hsusb1: usb@11eb0000 {
			compatible = "renesas,usbhs-r9a08g046",
				     "renesas,rzg2l-usbhs";
			reg = <0 0x11eb0000 0 0x10000>;
			interrupts = <GIC_SPI 127 IRQ_TYPE_EDGE_RISING>,
				     <GIC_SPI 128 IRQ_TYPE_LEVEL_HIGH>,
				     <GIC_SPI 129 IRQ_TYPE_LEVEL_HIGH>,
				     <GIC_SPI 126 IRQ_TYPE_LEVEL_HIGH>;
			clocks = <&cpg CPG_MOD R9A08G046_USB_PCLK>,
				 <&cpg CPG_MOD R9A08G046_USB_U2P1_EXR_CPUCLK>;
			resets = <&phyrst 1>,
				 <&cpg R9A08G046_USB_U2P1_EXL_SYSRST>;
			renesas,buswait = <7>;
			phys = <&usb2_phy1 3>;
			phy-names = "usb";
			power-domains = <&cpg>;
			status = "disabled";
		};

		xspi: spi@10060000 {
			compatible = "renesas,r9a08g046-xspi";
			reg = <0 0x10060000 0 0x10000>,
			      <0 0x20000000 0 0x10000000>;
			reg-names = "regs", "dirmap";
			clocks = <&cpg CPG_MOD R9A08G046_XSPI_CLK>,
				 <&cpg CPG_MOD R9A08G046_XSPI_HCLK>,
				 <&cpg CPG_MOD R9A08G046_XSPI_ACLK>,
				 <&cpg CPG_MOD R9A08G046_XSPI_CLKX2>;
			clock-names = "spi", "spihclk", "spiaclk", "spix2";
			resets = <&cpg R9A08G046_XSPI_HRESETN>,
				 <&cpg R9A08G046_XSPI_ARESETN>;
			power-domains = <&cpg>;
			#address-cells = <1>;
			#size-cells = <0>;
			status = "disabled";
		};

		gic: interrupt-controller@12400000 {
			compatible = "arm,gic-v3";
			#interrupt-cells = <3>;
			#address-cells = <0>;
			interrupt-controller;
			reg = <0x0 0x12400000 0 0x40000>,
			      <0x0 0x12440000 0 0x80000>;
			interrupts = <GIC_PPI 9 IRQ_TYPE_LEVEL_LOW>;
		};

		wdt0: watchdog@12800800 {
			compatible = "renesas,r9a08g046-wdt",
				     "renesas,rzg2l-wdt";
			reg = <0 0x12800800 0 0x400>;
			clocks = <&cpg CPG_MOD R9A08G046_WDT0_PCLK>,
				 <&cpg CPG_MOD R9A08G046_WDT0_CLK>;
			clock-names = "pclk", "oscclk";
			interrupts = <GIC_SPI 53 IRQ_TYPE_LEVEL_HIGH>,
				     <GIC_SPI 52 IRQ_TYPE_LEVEL_HIGH>;
			interrupt-names = "wdt", "perrout";
			resets = <&cpg R9A08G046_WDT0_PRESETN>;
			power-domains = <&cpg>;
			status = "disabled";
		};

		wdt1: watchdog@12800400 {
			compatible = "renesas,r9a08g046-wdt",
				     "renesas,rzg2l-wdt";
			reg = <0 0x12800400 0 0x400>;
			clocks = <&cpg CPG_MOD R9A08G046_WDT1_PCLK>,
				 <&cpg CPG_MOD R9A08G046_WDT1_CLK>;
			clock-names = "pclk", "oscclk";
			interrupts = <GIC_SPI 55 IRQ_TYPE_LEVEL_HIGH>,
				     <GIC_SPI 54 IRQ_TYPE_LEVEL_HIGH>;
			interrupt-names = "wdt", "perrout";
			resets = <&cpg R9A08G046_WDT1_PRESETN>;
			power-domains = <&cpg>;
			status = "disabled";
		};

		ostm0: timer@12801000 {
			compatible = "renesas,r9a08g046-ostm",
				     "renesas,ostm";
			reg = <0x0 0x12801000 0x0 0x400>;
			interrupts = <GIC_SPI 49 IRQ_TYPE_EDGE_RISING>;
			clocks = <&cpg CPG_MOD R9A08G046_OSTM0_PCLK>;
			resets = <&cpg R9A08G046_OSTM0_PRESETZ>;
			power-domains = <&cpg>;
			status = "disabled";
		};

		ostm1: timer@12801400 {
			compatible = "renesas,r9a08g046-ostm",
				     "renesas,ostm";
			reg = <0x0 0x12801400 0x0 0x400>;
			interrupts = <GIC_SPI 50 IRQ_TYPE_EDGE_RISING>;
			clocks = <&cpg CPG_MOD R9A08G046_OSTM1_PCLK>;
			resets = <&cpg R9A08G046_OSTM1_PRESETZ>;
			power-domains = <&cpg>;
			status = "disabled";
		};

		ostm2: timer@12801800 {
			compatible = "renesas,r9a08g045-ostm",
				     "renesas,ostm";
			reg = <0x0 0x12801800 0x0 0x400>;
			interrupts = <GIC_SPI 51 IRQ_TYPE_EDGE_RISING>;
			clocks = <&cpg CPG_MOD R9A08G046_OSTM2_PCLK>;
			resets = <&cpg R9A08G046_OSTM2_PRESETZ>;
			power-domains = <&cpg>;
			status = "disabled";
		};

		rsci1: spi@100f1000 {
			compatible = "renesas,r9a08g046-rz-rsci";
			reg = <0 0x100f1000 0 0x1000>;
			interrupts = <GIC_SPI 422 IRQ_TYPE_LEVEL_HIGH>,
				     <GIC_SPI 423 IRQ_TYPE_EDGE_RISING>,
				     <GIC_SPI 424 IRQ_TYPE_EDGE_RISING>,
				     <GIC_SPI 425 IRQ_TYPE_LEVEL_HIGH>;
			interrupt-names = "eri", "rxi", "txi", "tei";
			clocks = <&cpg CPG_MOD R9A08G046_RSCI1_PCLK>,
				 <&cpg CPG_MOD R9A08G046_RSCI1_TCLK>;
			clock-names = "fck", "tclk";
			power-domains = <&cpg>;
			resets = <&cpg R9A08G046_RSCI1_PRESETN>,
				 <&cpg R9A08G046_RSCI1_TRESETN>;
			reset-names = "presetn", "tresetn";
			dmas = <&dmac 0xc6d9>, <&dmac 0xc6da>;
			dma-names = "tx", "rx";
			status = "disabled";
		};

		rsci2: spi@100f2000 {
			compatible = "renesas,r9a08g046-rz-rsci";
			reg = <0 0x100f2000 0 0x1000>;
			interrupts = <GIC_SPI 428 IRQ_TYPE_LEVEL_HIGH>,
				     <GIC_SPI 429 IRQ_TYPE_EDGE_RISING>,
				     <GIC_SPI 430 IRQ_TYPE_EDGE_RISING>,
				     <GIC_SPI 431 IRQ_TYPE_LEVEL_HIGH>;
			interrupt-names = "eri", "rxi", "txi", "tei";
			clocks = <&cpg CPG_MOD R9A08G046_RSCI2_PCLK>,
				 <&cpg CPG_MOD R9A08G046_RSCI2_TCLK>;
			clock-names = "fck", "tclk";
			power-domains = <&cpg>;
			resets = <&cpg R9A08G046_RSCI2_PRESETN>,
				 <&cpg R9A08G046_RSCI2_TRESETN>;
			reset-names = "presetn", "tresetn";
			dmas = <&dmac 0xc6e1>, <&dmac 0xc6e2>;
			dma-names = "tx", "rx";
			status = "disabled";
		};

		rsci3: spi@100f3000 {
			compatible = "renesas,r9a08g046-rz-rsci";
			reg = <0 0x100f3000 0 0x1000>;
			interrupts = <GIC_SPI 434 IRQ_TYPE_LEVEL_HIGH>,
				     <GIC_SPI 435 IRQ_TYPE_EDGE_RISING>,
				     <GIC_SPI 436 IRQ_TYPE_EDGE_RISING>,
				     <GIC_SPI 437 IRQ_TYPE_LEVEL_HIGH>;
			interrupt-names = "eri", "rxi", "txi", "tei";
			clocks = <&cpg CPG_MOD R9A08G046_RSCI3_PCLK>,
				 <&cpg CPG_MOD R9A08G046_RSCI3_TCLK>;
			clock-names = "fck", "tclk";
			power-domains = <&cpg>;
			resets = <&cpg R9A08G046_RSCI3_PRESETN>,
				 <&cpg R9A08G046_RSCI3_TRESETN>;
			reset-names = "presetn", "tresetn";
			dmas = <&dmac 0xc6e9>, <&dmac 0xc6ea>;
			dma-names = "tx", "rx";
			status = "disabled";
		};

		spi0: spi@100b0000 {
			compatible = "renesas,rspi-g3l";
			reg = <0 0x100b0000 0 0x400>;
			interrupts = <GIC_SPI 442 IRQ_TYPE_EDGE_RISING>,
				     <GIC_SPI 443 IRQ_TYPE_EDGE_RISING>,
				     <GIC_SPI 444 IRQ_TYPE_EDGE_RISING>;
			interrupt-names = "error", "rx", "tx";
			clocks = <&cpg CPG_MOD R9A08G046_RSPI0_PCLK>,
				 <&cpg CPG_MOD R9A08G046_RSPI0_TCLK>;
			clock-names = "pclk", "tclk";
			resets = <&cpg R9A08G046_RSPI0_PRESETN>,
				 <&cpg R9A08G046_RSPI0_TRESETN>;
			reset-names = "presetn", "tresetn";
			dmas = <&dmac 0x26F1>, <&dmac 0x26F2>;
			dma-names = "tx", "rx";
			power-domains = <&cpg>;
			num-cs = <1>;
			#address-cells = <1>;
			#size-cells = <0>;
			status = "disabled";
		};

		spi1: spi@100e9000 {
			compatible = "renesas,rspi-g3l";
			reg = <0 0x100e9000 0 0x400>;
			interrupts = <GIC_SPI 447 IRQ_TYPE_EDGE_RISING>,
				     <GIC_SPI 448 IRQ_TYPE_EDGE_RISING>,
				     <GIC_SPI 449 IRQ_TYPE_EDGE_RISING>;
			interrupt-names = "error", "rx", "tx";
			clocks = <&cpg CPG_MOD R9A08G046_RSPI1_PCLK>,
				 <&cpg CPG_MOD R9A08G046_RSPI1_TCLK>;
			clock-names = "pclk", "tclk";
			resets = <&cpg R9A08G046_RSPI1_PRESETN>,
				 <&cpg R9A08G046_RSPI1_TRESETN>;
			reset-names = "presetn", "tresetn";
			dmas = <&dmac 0x26F5>, <&dmac 0x26F6>;
			dma-names = "tx", "rx";
			power-domains = <&cpg>;
			num-cs = <1>;
			#address-cells = <1>;
			#size-cells = <0>;
			status = "disabled";
		};

		spi2: spi@100ea000 {
			compatible = "renesas,rspi-g3l";
			reg = <0 0x100ea000 0 0x400>;
			interrupts = <GIC_SPI 452 IRQ_TYPE_EDGE_RISING>,
				     <GIC_SPI 453 IRQ_TYPE_EDGE_RISING>,
				     <GIC_SPI 454 IRQ_TYPE_EDGE_RISING>;
			interrupt-names = "error", "rx", "tx";
			clocks = <&cpg CPG_MOD R9A08G046_RSPI2_PCLK>,
				 <&cpg CPG_MOD R9A08G046_RSPI2_TCLK>;
			clock-names = "pclk", "tclk";
			resets = <&cpg R9A08G046_RSPI2_PRESETN>,
				 <&cpg R9A08G046_RSPI2_TRESETN>;
			reset-names = "presetn", "tresetn";
			dmas = <&dmac 0x26F9>, <&dmac 0x26FA>;
			dma-names = "tx", "rx";
			power-domains = <&cpg>;
			num-cs = <1>;
			#address-cells = <1>;
			#size-cells = <0>;
			status = "disabled";
		};

		fcpcs: vcp4@10820000 {
			compatible = "renesas,vcp4-fcpcs";
			reg = <0 0x10820000 0 0x200>;
			renesas,#ch = <0>;
		};

		vcpl4: vcp4@10800000 {
			compatible = "renesas,vcp4-vcpl4";
			reg = <0 0x10800000 0 0x200>,
				      <0 0x10810200 0 0x200>;
			interrupts = <GIC_SPI 190 IRQ_TYPE_LEVEL_HIGH>,
				     <GIC_SPI 191 IRQ_TYPE_LEVEL_HIGH>;
			clocks = <&cpg CPG_MOD R9A08G046_H264_CLK_A>,
				 <&cpg CPG_MOD R9A08G046_H264_CLK_P>;
			power-domains = <&cpg>;
			resets = <&cpg R9A08G046_H264_X_RESET_VCP>,
				 <&cpg R9A08G046_H264_CP_PRESET_P>;
			renesas,#ch = <0>;
			renesas,#fcp_ch = <0>;
		};

		isu2: isum@10840000 {
			compatible = "renesas,isum";
			reg = <0 0x10840000 0 0x01F4>;
			interrupts = <GIC_SPI 183 IRQ_TYPE_EDGE_RISING>,
				     <GIC_SPI 184 IRQ_TYPE_EDGE_RISING>,
				     <GIC_SPI 185 IRQ_TYPE_EDGE_RISING>,
				     <GIC_SPI 186 IRQ_TYPE_EDGE_RISING>,
				     <GIC_SPI 187 IRQ_TYPE_LEVEL_HIGH>,
				     <GIC_SPI 188 IRQ_TYPE_LEVEL_HIGH>,
				     <GIC_SPI 189 IRQ_TYPE_LEVEL_HIGH>;
			clocks = <&cpg CPG_MOD R9A08G046_ISU_ACLK>,
				 <&cpg CPG_MOD R9A08G046_ISU_PCLK>;
			clock-names = "isu_aclk", "isu_pclk";
			resets = <&cpg R9A08G046_ISU_ARESETN>,
				 <&cpg R9A08G046_ISU_PRESETN>;
			reset-names = "aresetn", "presetn";
			renesas,#ch = <0>;
			renesas,#rpf = <1>;
			renesas,#wpf = <1>;
			renesas,has-rs;
			power-domains = <&cpg>;
		};

		canfd: can@100c0000 {
			compatible = "renesas,r9a08g046-canfd";
			reg = <0 0x100c0000 0 0x20000>;
			interrupts = <GIC_SPI 455 IRQ_TYPE_LEVEL_HIGH>,
				     <GIC_SPI 456 IRQ_TYPE_LEVEL_HIGH>,
				     <GIC_SPI 457 IRQ_TYPE_LEVEL_HIGH>,
				     <GIC_SPI 458 IRQ_TYPE_LEVEL_HIGH>,
				     <GIC_SPI 459 IRQ_TYPE_LEVEL_HIGH>,
				     <GIC_SPI 463 IRQ_TYPE_LEVEL_HIGH>,
				     <GIC_SPI 464 IRQ_TYPE_LEVEL_HIGH>,
				     <GIC_SPI 465 IRQ_TYPE_LEVEL_HIGH>,
				     <GIC_SPI 469 IRQ_TYPE_LEVEL_HIGH>,
				     <GIC_SPI 470 IRQ_TYPE_LEVEL_HIGH>,
				     <GIC_SPI 471 IRQ_TYPE_LEVEL_HIGH>;
			interrupt-names = "g_err", "g_recc",
					  "ch0_err", "ch0_rec", "ch0_trx",
					  "ch1_err", "ch1_rec", "ch1_trx",
					  "ch2_err", "ch2_rec", "ch2_trx";
			clocks = <&cpg CPG_MOD R9A08G046_CANFD_PCLK>,
				 <&cpg CPG_MOD R9A08G046_CANFD_CLK_RAM>,
				 <&cpg CPG_CORE R9A08G046_CLK_P4_DIV2>,
				 <&can_clk>;
			clock-names = "fck", "ram_clk", "canfd", "can_clk";
			assigned-clocks = <&cpg CPG_CORE R9A08G046_CLK_P4_DIV2>;
			assigned-clock-rates = <80000000>;
			resets = <&cpg R9A08G046_CANFD_RSTP_N>, <&cpg R9A08G046_CANFD_RSTC_N>;
			reset-names = "rstp_n", "rstc_n";
			power-domains = <&cpg>;
			status = "disabled";

			channel0 {
				status = "disabled";
			};
			channel1 {
				status = "disabled";
			};
			channel2 {
				status = "disabled";
			};
		};

		pcie: pcie@11e40000 {
			compatible = "renesas,r9a08g046-pcie";
			reg = <0 0x11e40000 0 0x10000>;
			ranges = <0x02000000 0 0x30000000 0 0x30000000 0 0x8000000>;
			/* Map all possible DRAM ranges (4 GB). */
			dma-ranges = <0x42000000 0 0x40000000 0 0x40000000 0x1 0x0>;
			bus-range = <0x0 0xff>;
			clocks = <&cpg CPG_MOD R9A08G046_PCI_ACLK>,
				 <&cpg CPG_MOD R9A08G046_PCI_CLKL1PM>,
				 <&cpg CPG_MOD R9A08G046_PCI_CLK_PMU>;
			clock-names = "aclk", "pm", "pmu";
			resets = <&cpg R9A08G046_PCI_ARESETN>;
			reset-names = "aresetn";
			interrupts = <GIC_SPI 483 IRQ_TYPE_LEVEL_HIGH>,
				     <GIC_SPI 484 IRQ_TYPE_LEVEL_HIGH>,
				     <GIC_SPI 485 IRQ_TYPE_LEVEL_HIGH>,
				     <GIC_SPI 486 IRQ_TYPE_LEVEL_HIGH>,
				     <GIC_SPI 487 IRQ_TYPE_LEVEL_HIGH>,
				     <GIC_SPI 488 IRQ_TYPE_LEVEL_HIGH>,
				     <GIC_SPI 489 IRQ_TYPE_LEVEL_HIGH>,
				     <GIC_SPI 490 IRQ_TYPE_LEVEL_HIGH>,
				     <GIC_SPI 491 IRQ_TYPE_LEVEL_HIGH>,
				     <GIC_SPI 492 IRQ_TYPE_LEVEL_HIGH>,
				     <GIC_SPI 493 IRQ_TYPE_LEVEL_HIGH>,
				     <GIC_SPI 494 IRQ_TYPE_LEVEL_HIGH>,
				     <GIC_SPI 495 IRQ_TYPE_LEVEL_HIGH>,
				     <GIC_SPI 496 IRQ_TYPE_LEVEL_HIGH>,
				     <GIC_SPI 497 IRQ_TYPE_LEVEL_HIGH>,
				     <GIC_SPI 498 IRQ_TYPE_LEVEL_HIGH>;
			interrupt-names = "serr", "serr_cor", "serr_nonfatal",
					  "serr_fatal", "axi_err", "inta",
					  "intb", "intc", "intd", "msi",
					  "link_bandwidth", "pm_pme", "dma",
					  "pcie_evt", "msg", "all";
			#interrupt-cells = <1>;
			interrupt-controller;
			interrupt-map-mask = <0 0 0 7>;
			interrupt-map = <0 0 0 1 &pcie 0 0 0 0>, /* INT A */
					<0 0 0 2 &pcie 0 0 0 1>, /* INT B */
					<0 0 0 3 &pcie 0 0 0 2>, /* INT C */
					<0 0 0 4 &pcie 0 0 0 3>; /* INT D */
			device_type = "pci";
			num-lanes = <1>;
			#address-cells = <3>;
			#size-cells = <2>;
			pcie,channel = <0>;
			power-domains = <&cpg>;
			vendor-id = <0x1912>;
			device-id = <0x0033>;
			renesas,sysc = <&sysc>;
			status = "disabled";
		};

		gpt: pwm@10048000 {
			compatible = "renesas,r9a08g046-gpt",
				     "renesas,rzg3l-gpt";
			reg = <0 0x10048000 0 0x800>;
			#pwm-cells = <3>;
			interrupts = <GIC_SPI 201 IRQ_TYPE_EDGE_RISING>,
				     <GIC_SPI 202 IRQ_TYPE_EDGE_RISING>,
				     <GIC_SPI 203 IRQ_TYPE_EDGE_RISING>,
				     <GIC_SPI 204 IRQ_TYPE_EDGE_RISING>,
				     <GIC_SPI 205 IRQ_TYPE_EDGE_RISING>,
				     <GIC_SPI 206 IRQ_TYPE_EDGE_RISING>,
				     <GIC_SPI 207 IRQ_TYPE_EDGE_RISING>,
				     <GIC_SPI 208 IRQ_TYPE_EDGE_RISING>,
				     <GIC_SPI 212 IRQ_TYPE_EDGE_RISING>,
				     <GIC_SPI 213 IRQ_TYPE_EDGE_RISING>,
				     <GIC_SPI 214 IRQ_TYPE_EDGE_RISING>,
				     <GIC_SPI 215 IRQ_TYPE_EDGE_RISING>,
				     <GIC_SPI 216 IRQ_TYPE_EDGE_RISING>,
				     <GIC_SPI 217 IRQ_TYPE_EDGE_RISING>,
				     <GIC_SPI 218 IRQ_TYPE_EDGE_RISING>,
				     <GIC_SPI 219 IRQ_TYPE_EDGE_RISING>,
				     <GIC_SPI 220 IRQ_TYPE_EDGE_RISING>,
				     <GIC_SPI 224 IRQ_TYPE_EDGE_RISING>,
				     <GIC_SPI 225 IRQ_TYPE_EDGE_RISING>,
				     <GIC_SPI 226 IRQ_TYPE_EDGE_RISING>,
				     <GIC_SPI 227 IRQ_TYPE_EDGE_RISING>,
				     <GIC_SPI 228 IRQ_TYPE_EDGE_RISING>,
				     <GIC_SPI 229 IRQ_TYPE_EDGE_RISING>,
				     <GIC_SPI 230 IRQ_TYPE_EDGE_RISING>,
				     <GIC_SPI 231 IRQ_TYPE_EDGE_RISING>,
				     <GIC_SPI 232 IRQ_TYPE_EDGE_RISING>,
				     <GIC_SPI 236 IRQ_TYPE_EDGE_RISING>,
				     <GIC_SPI 237 IRQ_TYPE_EDGE_RISING>,
				     <GIC_SPI 238 IRQ_TYPE_EDGE_RISING>,
				     <GIC_SPI 239 IRQ_TYPE_EDGE_RISING>,
				     <GIC_SPI 240 IRQ_TYPE_EDGE_RISING>,
				     <GIC_SPI 241 IRQ_TYPE_EDGE_RISING>,
				     <GIC_SPI 242 IRQ_TYPE_EDGE_RISING>,
				     <GIC_SPI 243 IRQ_TYPE_EDGE_RISING>,
				     <GIC_SPI 244 IRQ_TYPE_EDGE_RISING>,
				     <GIC_SPI 248 IRQ_TYPE_EDGE_RISING>,
				     <GIC_SPI 249 IRQ_TYPE_EDGE_RISING>,
				     <GIC_SPI 250 IRQ_TYPE_EDGE_RISING>,
				     <GIC_SPI 251 IRQ_TYPE_EDGE_RISING>,
				     <GIC_SPI 252 IRQ_TYPE_EDGE_RISING>,
				     <GIC_SPI 253 IRQ_TYPE_EDGE_RISING>,
				     <GIC_SPI 254 IRQ_TYPE_EDGE_RISING>,
				     <GIC_SPI 255 IRQ_TYPE_EDGE_RISING>,
				     <GIC_SPI 256 IRQ_TYPE_EDGE_RISING>,
				     <GIC_SPI 260 IRQ_TYPE_EDGE_RISING>,
				     <GIC_SPI 261 IRQ_TYPE_EDGE_RISING>,
				     <GIC_SPI 262 IRQ_TYPE_EDGE_RISING>,
				     <GIC_SPI 263 IRQ_TYPE_EDGE_RISING>,
				     <GIC_SPI 264 IRQ_TYPE_EDGE_RISING>,
				     <GIC_SPI 265 IRQ_TYPE_EDGE_RISING>,
				     <GIC_SPI 266 IRQ_TYPE_EDGE_RISING>,
				     <GIC_SPI 267 IRQ_TYPE_EDGE_RISING>,
				     <GIC_SPI 268 IRQ_TYPE_EDGE_RISING>,
				     <GIC_SPI 272 IRQ_TYPE_EDGE_RISING>,
				     <GIC_SPI 273 IRQ_TYPE_EDGE_RISING>,
				     <GIC_SPI 274 IRQ_TYPE_EDGE_RISING>,
				     <GIC_SPI 275 IRQ_TYPE_EDGE_RISING>,
				     <GIC_SPI 276 IRQ_TYPE_EDGE_RISING>,
				     <GIC_SPI 277 IRQ_TYPE_EDGE_RISING>,
				     <GIC_SPI 278 IRQ_TYPE_EDGE_RISING>,
				     <GIC_SPI 279 IRQ_TYPE_EDGE_RISING>,
				     <GIC_SPI 280 IRQ_TYPE_EDGE_RISING>,
				     <GIC_SPI 284 IRQ_TYPE_EDGE_RISING>,
				     <GIC_SPI 285 IRQ_TYPE_EDGE_RISING>,
				     <GIC_SPI 286 IRQ_TYPE_EDGE_RISING>,
				     <GIC_SPI 287 IRQ_TYPE_EDGE_RISING>,
				     <GIC_SPI 288 IRQ_TYPE_EDGE_RISING>,
				     <GIC_SPI 289 IRQ_TYPE_EDGE_RISING>,
				     <GIC_SPI 290 IRQ_TYPE_EDGE_RISING>,
				     <GIC_SPI 291 IRQ_TYPE_EDGE_RISING>,
				     <GIC_SPI 292 IRQ_TYPE_EDGE_RISING>,
				     <GIC_SPI 296 IRQ_TYPE_EDGE_RISING>;
			interrupt-names = "gtcia_n_0", "gtcib_n_0", "gtcic_n_0", "gtcid_n_0",
					  "gtcie_n_0", "gtcif_n_0", "gtciada_n_0", "gtciadb_n_0",
					  "gtciv_n_0",
					  "gtcia_n_1", "gtcib_n_1", "gtcic_n_1", "gtcid_n_1",
					  "gtcie_n_1", "gtcif_n_1", "gtciada_n_1", "gtciadb_n_1",
					  "gtciv_n_1",
					  "gtcia_n_2", "gtcib_n_2", "gtcic_n_2", "gtcid_n_2",
					  "gtcie_n_2", "gtcif_n_2", "gtciada_n_2", "gtciadb_n_2",
					  "gtciv_n_2",
					  "gtcia_n_3", "gtcib_n_3", "gtcic_n_3", "gtcid_n_3",
					  "gtcie_n_3", "gtcif_n_3", "gtciada_n_3", "gtciadb_n_3",
					  "gtciv_n_3",
					  "gtcia_n_4", "gtcib_n_4", "gtcic_n_4", "gtcid_n_4",
					  "gtcie_n_4", "gtcif_n_4", "gtciada_n_4", "gtciadb_n_4",
					  "gtciv_n_4",
					  "gtcia_n_5", "gtcib_n_5", "gtcic_n_5", "gtcid_n_5",
					  "gtcie_n_5", "gtcif_n_5", "gtciada_n_5", "gtciadb_n_5",
					  "gtciv_n_5",
					  "gtcia_n_6", "gtcib_n_6", "gtcic_n_6", "gtcid_n_6",
					  "gtcie_n_6", "gtcif_n_6", "gtciada_n_6", "gtciadb_n_6",
					  "gtciv_n_6",
					  "gtcia_n_7", "gtcib_n_7", "gtcic_n_7", "gtcid_n_7",
					  "gtcie_n_7", "gtcif_n_7", "gtciada_n_7", "gtciadb_n_7",
					  "gtciv_n_7";
			clocks = <&cpg CPG_MOD R9A08G046_GPT_PCLK>;
			resets = <&cpg R9A08G046_GPT_RST_C>;
			power-domains = <&cpg>;
			renesas,icu = <&icu>;
			status = "disabled";
		};

		poega: poega@10048800 {
			compatible = "renesas,poeg-r9a08g046",
				     "renesas,poeg-r9a07g044";
			reg = <0 0x10048800 0 0x04>;
			interrupts = <GIC_SPI 301 IRQ_TYPE_LEVEL_HIGH>;
			clocks = <&cpg CPG_MOD R9A08G046_POEG_A_CLKP>;
			resets = <&cpg R9A08G046_POEG_A_RST>;
			power-domains = <&cpg>;
			status = "disabled";
		};

		poegb: poegb@10048C00 {
			compatible = "renesas,poeg-r9a08g046",
				     "renesas,poeg-r9a07g044";
			reg = <0 0x10048C00 0 0x04>;
			interrupts = <GIC_SPI 302 IRQ_TYPE_LEVEL_HIGH>;
			clocks = <&cpg CPG_MOD R9A08G046_POEG_B_CLKP>;
			resets = <&cpg R9A08G046_POEG_B_RST>;
			power-domains = <&cpg>;
			status = "disabled";
		};

		poegc: poegc@10049000 {
			compatible = "renesas,poeg-r9a08g046",
				     "renesas,poeg-r9a07g044";
			reg = <0 0x10049000 0 0x04>;
			interrupts = <GIC_SPI 303 IRQ_TYPE_LEVEL_HIGH>;
			clocks = <&cpg CPG_MOD R9A08G046_POEG_C_CLKP>;
			resets = <&cpg R9A08G046_POEG_C_RST>;
			power-domains = <&cpg>;
			status = "disabled";
		};

		poegd: poegd@10049400 {
			compatible = "renesas,poeg-r9a08g046",
				     "renesas,poeg-r9a07g044";
			reg = <0 0x10049400 0 0x04>;
			interrupts = <GIC_SPI 304 IRQ_TYPE_LEVEL_HIGH>;
			clocks = <&cpg CPG_MOD R9A08G046_POEG_D_CLKP>;
			resets = <&cpg R9A08G046_POEG_D_RST>;
			power-domains = <&cpg>;
			status = "disabled";
		};

		cru: video0@10830000 {
			compatible = "renesas,rzg3l-cru";
			reg = <0 0x10830000 0 0x400>;
			clocks = <&cpg CPG_MOD R9A08G046_CRU_VCLK>,
				 <&cpg CPG_MOD R9A08G046_CRU_PCLK>,
				 <&cpg CPG_MOD R9A08G046_CRU_ACLK>;
			clock-names = "video", "pclk", "aclk";
			interrupts = <GIC_SPI 196 IRQ_TYPE_LEVEL_HIGH>;
			resets = <&cpg R9A08G046_CRU_PRESETN>,
				 <&cpg R9A08G046_CRU_ARESETN>;
			reset-names = "presetn", "aresetn";
			power-domains = <&cpg>;
			channel,id = <0>;
			status = "disabled";

			ports {
				#address-cells = <1>;
				#size-cells = <0>;

				port@1 {
					reg = <1>;

					cru_to_csi2: endpoint {
						remote-endpoint = <&csi2_to_cru>;
					};
				};
			};
		};

		csi2: csi2@10830400 {
			compatible = "renesas,rzg3l-csi2";
			reg = <0 0x10830400 0 0xc00>;
			interrupts = <GIC_SPI 195 IRQ_TYPE_LEVEL_HIGH>;
			clocks = <&cpg CPG_MOD R9A08G046_CRU_VCLK>,
				 <&cpg CPG_MOD R9A08G046_CRU_SYSCLK>,
				 <&cpg CPG_MOD R9A08G046_CRU_PCLK>;
			clock-names = "video", "system";
			resets = <&cpg R9A08G046_CRU_CMN_RSTB>,
				 <&cpg R9A08G046_CRU_PRESETN>;
			reset-names = "cmn-rstb", "presetn";
			power-domains = <&cpg>;
			status = "disabled";

			ports {
				#address-cells = <1>;
				#size-cells = <0>;

				port@1 {
					reg = <1>;

					csi2_to_cru: endpoint {
						remote-endpoint = <&cru_to_csi2>;
					};
				};
			};
		};
		
		mtu3: timer@10001200 {
			compatible = "renesas,r9a08g046-mtu3",
				     "renesas,rz-mtu3";
			reg = <0 0x10001200 0 0xb00>;
			#pwm-cells = <2>;
			interrupts = <GIC_SPI 205 IRQ_TYPE_EDGE_RISING>,
				     <GIC_SPI 206 IRQ_TYPE_EDGE_RISING>,
				     <GIC_SPI 207 IRQ_TYPE_EDGE_RISING>,
				     <GIC_SPI 208 IRQ_TYPE_EDGE_RISING>,
				     <GIC_SPI 209 IRQ_TYPE_EDGE_RISING>,
				     <GIC_SPI 210 IRQ_TYPE_EDGE_RISING>,
				     <GIC_SPI 217 IRQ_TYPE_EDGE_RISING>,
				     <GIC_SPI 218 IRQ_TYPE_EDGE_RISING>,
				     <GIC_SPI 219 IRQ_TYPE_EDGE_RISING>,
				     <GIC_SPI 220 IRQ_TYPE_EDGE_RISING>,
				     <GIC_SPI 221 IRQ_TYPE_EDGE_RISING>,
				     <GIC_SPI 222 IRQ_TYPE_EDGE_RISING>,
				     <GIC_SPI 229 IRQ_TYPE_EDGE_RISING>,
				     <GIC_SPI 230 IRQ_TYPE_EDGE_RISING>,
				     <GIC_SPI 231 IRQ_TYPE_EDGE_RISING>,
				     <GIC_SPI 232 IRQ_TYPE_EDGE_RISING>,
				     <GIC_SPI 233 IRQ_TYPE_EDGE_RISING>,
				     <GIC_SPI 234 IRQ_TYPE_EDGE_RISING>,
				     <GIC_SPI 241 IRQ_TYPE_EDGE_RISING>,
				     <GIC_SPI 242 IRQ_TYPE_EDGE_RISING>,
				     <GIC_SPI 243 IRQ_TYPE_EDGE_RISING>,
				     <GIC_SPI 244 IRQ_TYPE_EDGE_RISING>,
				     <GIC_SPI 245 IRQ_TYPE_EDGE_RISING>,
				     <GIC_SPI 246 IRQ_TYPE_EDGE_RISING>,
				     <GIC_SPI 253 IRQ_TYPE_EDGE_RISING>,
				     <GIC_SPI 254 IRQ_TYPE_EDGE_RISING>,
				     <GIC_SPI 255 IRQ_TYPE_EDGE_RISING>,
				     <GIC_SPI 256 IRQ_TYPE_EDGE_RISING>,
				     <GIC_SPI 257 IRQ_TYPE_EDGE_RISING>,
				     <GIC_SPI 258 IRQ_TYPE_EDGE_RISING>,
				     <GIC_SPI 265 IRQ_TYPE_EDGE_RISING>,
				     <GIC_SPI 266 IRQ_TYPE_EDGE_RISING>,
				     <GIC_SPI 267 IRQ_TYPE_EDGE_RISING>,
				     <GIC_SPI 268 IRQ_TYPE_EDGE_RISING>,
				     <GIC_SPI 269 IRQ_TYPE_EDGE_RISING>,
				     <GIC_SPI 270 IRQ_TYPE_EDGE_RISING>,
				     <GIC_SPI 277 IRQ_TYPE_EDGE_RISING>,
				     <GIC_SPI 278 IRQ_TYPE_EDGE_RISING>,
				     <GIC_SPI 279 IRQ_TYPE_EDGE_RISING>,
				     <GIC_SPI 280 IRQ_TYPE_EDGE_RISING>,
				     <GIC_SPI 281 IRQ_TYPE_EDGE_RISING>,
				     <GIC_SPI 282 IRQ_TYPE_EDGE_RISING>,
				     <GIC_SPI 289 IRQ_TYPE_EDGE_RISING>,
				     <GIC_SPI 290 IRQ_TYPE_EDGE_RISING>;
			interrupt-names = "tgia0", "tgib0", "tgic0", "tgid0",
					  "tciv0", "tgie0", "tgif0",
					  "tgia1", "tgib1", "tciv1", "tciu1",
					  "tgia2", "tgib2", "tciv2", "tciu2",
					  "tgia3", "tgib3", "tgic3", "tgid3",
					  "tciv3",
					  "tgia4", "tgib4", "tgic4", "tgid4",
					  "tciv4",
					  "tgiu5", "tgiv5", "tgiw5",
					  "tgia6", "tgib6", "tgic6", "tgid6",
					  "tciv6",
					  "tgia7", "tgib7", "tgic7", "tgid7",
					  "tciv7",
					  "tgia8", "tgib8", "tgic8", "tgid8",
					  "tciv8";
			renesas,icu = <&icu>;
			clocks = <&cpg CPG_MOD R9A08G046_MTU_X_MCK_MTU3>;
			clock-names = "fck";
			power-domains = <&cpg>;
			resets = <&cpg R9A08G046_MTU_X_PRESET_MTU3>;
			status = "disabled";
		};

		poe3: poe3@10049800 {
			compatible = "renesas,r9a08g046-poe3",
				     "renesas,rz-poe3";
			reg = <0 0x10049800 0 0x18>;
			interrupts = <GIC_SPI 297 IRQ_TYPE_LEVEL_HIGH>,
				     <GIC_SPI 298 IRQ_TYPE_LEVEL_HIGH>,
				     <GIC_SPI 299 IRQ_TYPE_LEVEL_HIGH>,
				     <GIC_SPI 300 IRQ_TYPE_LEVEL_HIGH>;
			interrupt-names = "oei1", "oei2", "oei3", "oei4";
			clocks = <&cpg CPG_MOD R9A08G046_POE3_CLKM_POE>;
			clock-names = "fck";
			resets = <&cpg R9A08G046_POE3_RST_M_REG>;
			power-domains = <&cpg>;
			status = "disabled";
		};
	};

	stmmac_axi_setup: stmmac-axi-config {
		snps,lpi_en;
		snps,wr_osr_lmt = <0xf>;
		snps,rd_osr_lmt = <0xf>;
		snps,blen = <16 8 4 0 0 0 0>;
	};

	timer {
		compatible = "arm,armv8-timer";
		interrupts-extended = <&gic GIC_PPI 13 IRQ_TYPE_LEVEL_LOW>,
				      <&gic GIC_PPI 14 IRQ_TYPE_LEVEL_LOW>,
				      <&gic GIC_PPI 11 IRQ_TYPE_LEVEL_LOW>,
				      <&gic GIC_PPI 10 IRQ_TYPE_LEVEL_LOW>,
				      <&gic GIC_PPI 12 IRQ_TYPE_LEVEL_LOW>;
		interrupt-names = "sec-phys", "phys", "virt", "hyp-phys",
				  "hyp-virt";
	};

	vbattb_xtal: vbattb-xtal {
		compatible = "fixed-clock";
		#clock-cells = <0>;
		/* This value must be overridden by the board. */
		clock-frequency = <0>;
	};

	thermal-zones {
		cpu_thermal: cpu-thermal {
			polling-delay-passive = <250>;
			polling-delay = <1000>;
			thermal-sensors = <&tsu>;

			cooling-maps {
				map0 {
					trip = <&cpu_alert0>;
					cooling-device = <&cpu0 0 2>, <&cpu1 0 2>,
							 <&cpu2 0 2>, <&cpu3 0 2>;
					contribution = <1024>;
				};
			};

			trips {
				cpu_crit: cpu-critical {
					temperature = <110000>;
					hysteresis = <1000>;
					type = "critical";
				};

				cpu_alert1: trip-point1 {
					temperature = <90000>;
					hysteresis = <1000>;
					type = "passive";
				};

				cpu_alert0: trip-point0 {
					temperature = <85000>;
					hysteresis = <1000>;
					type = "passive";
				};
			};
		};
	};
};
